VERSION "HIPBNYYYYYYYYYYYYYYYYYYYYYYYYYYYYYYYYYYYYY/4/%%%/4/'%**4YYY///"

NS_ :

BS_:

BU_: Aceinna

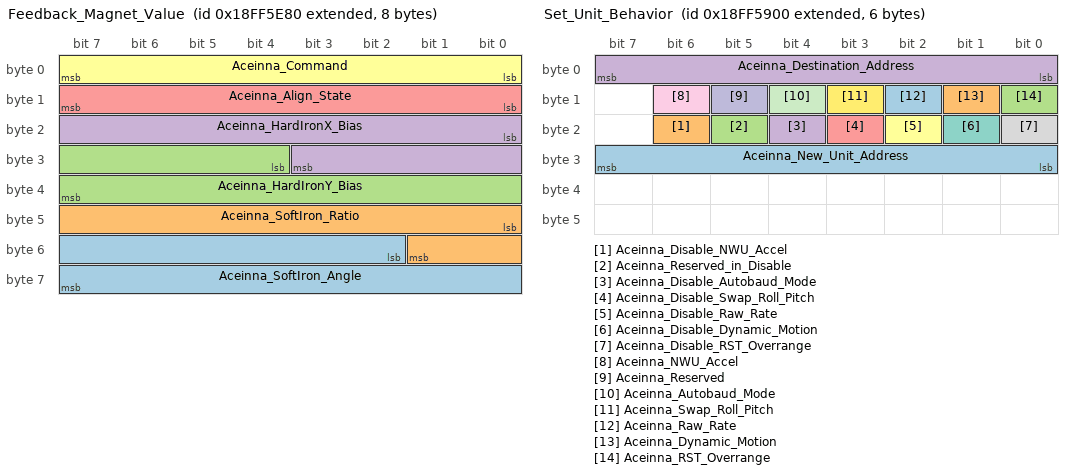
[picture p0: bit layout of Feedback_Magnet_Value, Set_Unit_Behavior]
BO_ 2566872704 Feedback_Magnet_Value: 8 Aceinna
 SG_ Aceinna_SoftIron_Angle : 50|14@1- (0.0015339,-3.14159) [-3.14|3.14] "rad" Vector__XXX
 SG_ Aceinna_SoftIron_Ratio : 40|10@1+ (0.0009765625,0) [0|0] "" Vector__XXX
 SG_ Aceinna_HardIronY_Bias : 28|12@1- (0.00390625,-8) [-8|8] "Gauss" Vector__XXX
 SG_ Aceinna_HardIronX_Bias : 16|12@1- (0.00390625,-8) [-8|8] "Gauss" Vector__XXX
 SG_ Aceinna_Align_State : 8|8@1+ (1,0) [0|0] "" Vector__XXX
 SG_ Aceinna_Command : 0|8@1+ (1,0) [0|0] "" Vector__XXX

BO_ 2566845313 Aceinna_GPS_lat_lon_: 8 Vector__XXX
 SG_ Aceinna_Lat : 0|32@1+ (0.0000001,-210) [-210|211] "deg" Vector__XXX
 SG_ Aceinna_Lon : 32|32@1+ (0.0000001,-210) [-210|211] "deg" Vector__XXX

BO_ 2566871296 Set_Unit_Behavior: 6 Vector__XXX
 SG_ Aceinna_New_Unit_Address : 24|8@1- (1,0) [0|0] "" Vector__XXX
 SG_ Aceinna_Disable_NWU_Accel : 22|1@1+ (1,0) [0|0] "" Vector__XXX
 SG_ Aceinna_Reserved_in_Disable : 21|1@1+ (1,0) [0|0] "" Vector__XXX
 SG_ Aceinna_Disable_Autobaud_Mode : 20|1@1+ (1,0) [0|0] "" Vector__XXX
 SG_ Aceinna_Disable_Swap_Roll_Pitch : 19|1@1+ (1,0) [0|0] "" Vector__XXX
 SG_ Aceinna_Disable_Raw_Rate : 18|1@1+ (1,0) [0|0] "" Vector__XXX
 SG_ Aceinna_Disable_Dynamic_Motion : 17|1@1+ (1,0) [0|0] "" Vector__XXX
 SG_ Aceinna_Disable_RST_Overrange : 16|1@1+ (1,0) [0|0] "" Vector__XXX
 SG_ Aceinna_NWU_Accel : 14|1@1+ (1,0) [0|0] "" Vector__XXX
 SG_ Aceinna_Reserved : 13|1@1+ (1,0) [0|0] "" Vector__XXX
 SG_ Aceinna_Autobaud_Mode : 12|1@1+ (1,0) [0|0] "" Vector__XXX
 SG_ Aceinna_Swap_Roll_Pitch : 11|1@1+ (1,0) [0|0] "" Vector__XXX
 SG_ Aceinna_Raw_Rate : 10|1@1+ (1,0) [0|0] "" Vector__XXX
 SG_ Aceinna_Dynamic_Motion : 9|1@1+ (1,0) [0|0] "" Vector__XXX
 SG_ Aceinna_RST_Overrange : 8|1@1+ (1,0) [0|0] "" Vector__XXX
 SG_ Aceinna_Destination_Address : 0|8@1- (1,0) [0|0] "" Vector__XXX

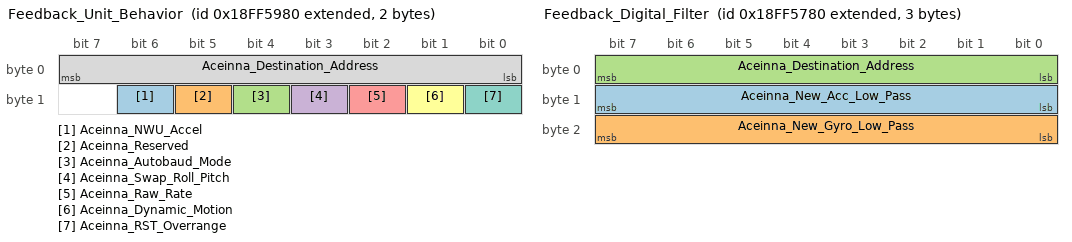
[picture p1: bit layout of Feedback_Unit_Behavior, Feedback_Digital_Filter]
BO_ 2566871424 Feedback_Unit_Behavior: 2 Vector__XXX
 SG_ Aceinna_NWU_Accel : 14|1@1+ (1,0) [0|0] "" Vector__XXX
 SG_ Aceinna_Reserved : 13|1@1+ (1,0) [0|0] "" Vector__XXX
 SG_ Aceinna_Autobaud_Mode : 12|1@1+ (1,0) [0|0] "" Vector__XXX
 SG_ Aceinna_Swap_Roll_Pitch : 11|1@1+ (1,0) [0|0] "" Vector__XXX
 SG_ Aceinna_Raw_Rate : 10|1@1+ (1,0) [0|0] "" Vector__XXX
 SG_ Aceinna_Dynamic_Motion : 9|1@1+ (1,0) [0|0] "" Vector__XXX
 SG_ Aceinna_RST_Overrange : 8|1@1+ (1,0) [0|0] "" Vector__XXX
 SG_ Aceinna_Destination_Address : 0|8@1- (1,0) [0|0] "" Vector__XXX

BO_ 2566870656 Feedback_Data_Pcket_Type: 2 Vector__XXX
 SG_ Aceinna_New_Packet_Type : 8|8@1- (1,0) [0|0] "" Vector__XXX
 SG_ Aceinna_Destination_Address : 0|8@1- (1,0) [0|0] "" Vector__XXX

BO_ 2566871168 Feedback_Orientation: 3 Vector__XXX
 SG_ Aceinna_New_Orientation_Type : 8|16@1- (1,0) [0|0] "" Vector__XXX
 SG_ Aceinna_Destination_Address : 0|8@1- (1,0) [0|0] "" Vector__XXX

BO_ 2566870912 Feedback_Digital_Filter: 3 Vector__XXX
 SG_ Aceinna_New_Acc_Low_Pass : 8|8@1- (1,0) [0|0] "" Vector__XXX
 SG_ Aceinna_New_Gyro_Low_Pass : 16|8@1- (1,0) [0|0] "" Vector__XXX
 SG_ Aceinna_Destination_Address : 0|8@1- (1,0) [0|0] "" Vector__XXX

BO_ 2566870400 Feedback_Packet_Rate_Divider: 2 Vector__XXX
 SG_ Aceinna_New_Pocket_Rate : 8|8@1- (1,0) [0|0] "" Vector__XXX
 SG_ Aceinna_Destination_Address : 0|8@1- (1,0) [0|0] "" Vector__XXX

BO_ 2565537536 Request_PGN: 3 Aceinna

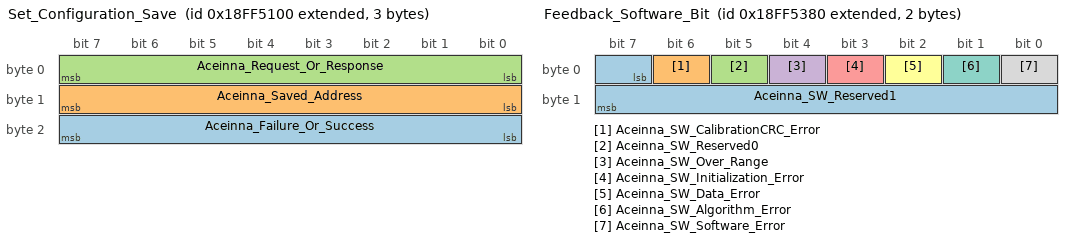
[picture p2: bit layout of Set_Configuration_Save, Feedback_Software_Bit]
BO_ 2566869248 Set_Configuration_Save: 3 Aceinna
 SG_ Aceinna_Failure_Or_Success : 16|8@1- (1,0) [0|0] "" Vector__XXX
 SG_ Aceinna_Saved_Address : 8|8@1- (1,0) [0|0] "" Vector__XXX
 SG_ Aceinna_Request_Or_Response : 0|8@1- (1,0) [0|0] "" Vector__XXX

BO_ 2566869888 Feedback_Software_Bit: 2 Aceinna
 SG_ Aceinna_SW_Reserved1 : 7|9@1+ (1,0) [0|0] "" Vector__XXX
 SG_ Aceinna_SW_CalibrationCRC_Error : 6|1@1+ (1,0) [0|0] "" Vector__XXX
 SG_ Aceinna_SW_Reserved0 : 5|1@1+ (1,0) [0|0] "" Vector__XXX
 SG_ Aceinna_SW_Over_Range : 4|1@1+ (1,0) [0|0] "" Vector__XXX
 SG_ Aceinna_SW_Initialization_Error : 3|1@1+ (1,0) [0|0] "" Vector__XXX
 SG_ Aceinna_SW_Data_Error : 2|1@1+ (1,0) [0|0] "" Vector__XXX
 SG_ Aceinna_SW_Algorithm_Error : 1|1@1+ (1,0) [0|0] "" Vector__XXX
 SG_ Aceinna_SW_Software_Error : 0|1@1+ (1,0) [0|0] "" Vector__XXX

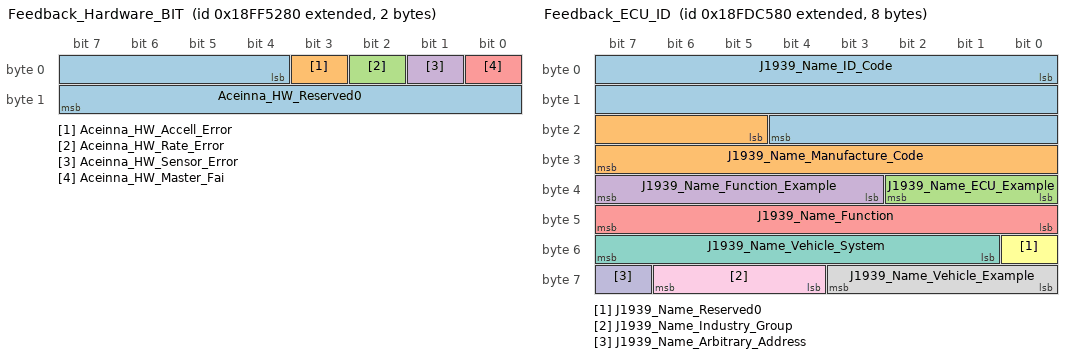
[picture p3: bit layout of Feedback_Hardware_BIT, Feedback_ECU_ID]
BO_ 2566869632 Feedback_Hardware_BIT: 2 Aceinna
 SG_ Aceinna_HW_Reserved0 : 4|12@1+ (1,0) [0|0] "" Vector__XXX
 SG_ Aceinna_HW_Accell_Error : 3|1@1+ (1,0) [0|0] "" Vector__XXX
 SG_ Aceinna_HW_Rate_Error : 2|1@1+ (1,0) [0|0] "" Vector__XXX
 SG_ Aceinna_HW_Sensor_Error : 1|1@1+ (1,0) [0|0] "" Vector__XXX
 SG_ Aceinna_HW_Master_Fai : 0|1@1+ (1,0) [0|0] "" Vector__XXX

BO_ 2566768000 Feedback_ECU_ID: 8 Aceinna
 SG_ J1939_Name_ID_Code : 0|21@1+ (1,0) [-16|15] "" Vector__XXX
 SG_ J1939_Name_Manufacture_Code : 21|11@1+ (1,0) [0|0] "" Vector__XXX
 SG_ J1939_Name_ECU_Example : 32|3@1+ (1,0) [-4|3] "" Vector__XXX
 SG_ J1939_Name_Function_Example : 35|5@1+ (1,0) [0|0] "" Vector__XXX
 SG_ J1939_Name_Function : 40|8@1+ (1,0) [0|0] "" Vector__XXX
 SG_ J1939_Name_Reserved0 : 48|1@1+ (1,0) [0|0] "" Vector__XXX
 SG_ J1939_Name_Vehicle_System : 49|7@1+ (1,0) [0|0] "" Vector__XXX
 SG_ J1939_Name_Vehicle_Example : 56|4@1+ (1,0) [0|0] "" Vector__XXX
 SG_ J1939_Name_Industry_Group : 60|3@1+ (1,0) [0|0] "" Vector__XXX
 SG_ J1939_Name_Arbitrary_Address : 63|1@1+ (1,0) [0|0] "" Vector__XXX

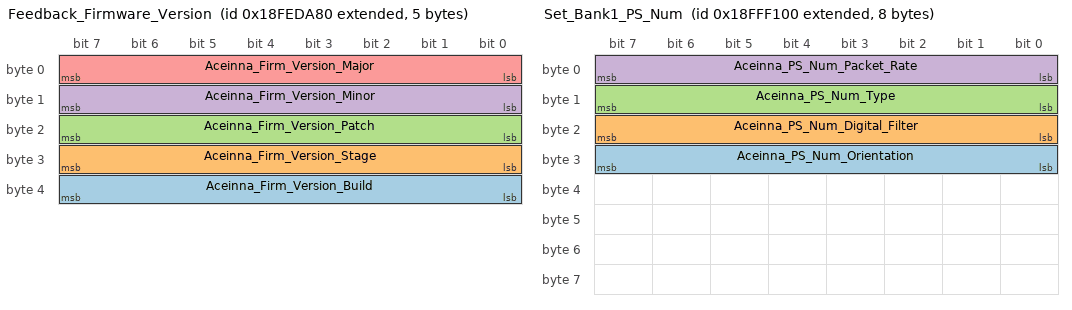
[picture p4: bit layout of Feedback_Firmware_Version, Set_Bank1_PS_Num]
BO_ 2566838912 Feedback_Firmware_Version: 5 Aceinna
 SG_ Aceinna_Firm_Version_Build : 32|8@1+ (1,0) [0|0] "" Vector__XXX
 SG_ Aceinna_Firm_Version_Stage : 24|8@1+ (1,0) [0|0] "" Vector__XXX
 SG_ Aceinna_Firm_Version_Patch : 16|8@1+ (1,0) [0|0] "" Vector__XXX
 SG_ Aceinna_Firm_Version_Minor : 8|8@1+ (1,0) [0|0] "" Vector__XXX
 SG_ Aceinna_Firm_Version_Major : 0|8@1+ (1,0) [0|0] "" Vector__XXX

BO_ 2566910208 Set_Bank1_PS_Num: 8 Aceinna
 SG_ Aceinna_PS_Num_Orientation : 24|8@1- (1,0) [0|0] "" Vector__XXX
 SG_ Aceinna_PS_Num_Digital_Filter : 16|8@1- (1,0) [0|0] "" Vector__XXX
 SG_ Aceinna_PS_Num_Type : 8|8@1- (1,0) [0|0] "" Vector__XXX
 SG_ Aceinna_PS_Num_Packet_Rate : 0|8@1- (1,0) [0|0] "" Vector__XXX

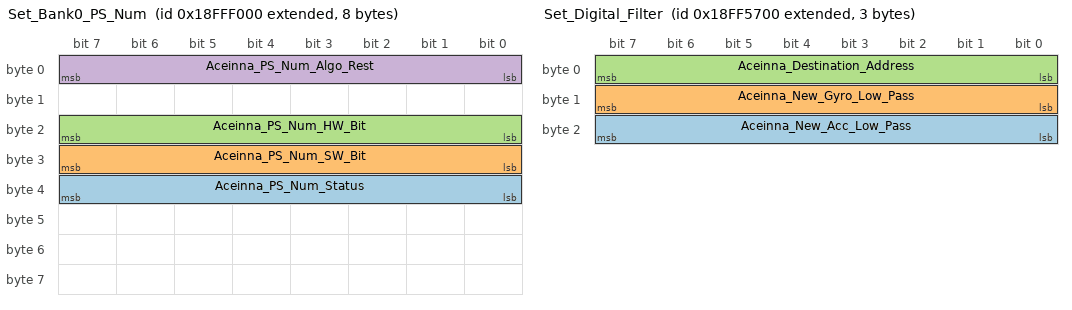
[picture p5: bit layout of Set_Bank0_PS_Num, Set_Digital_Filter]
BO_ 2566909952 Set_Bank0_PS_Num: 8 Aceinna
 SG_ Aceinna_PS_Num_Status : 32|8@1- (1,0) [0|0] "" Vector__XXX
 SG_ Aceinna_PS_Num_SW_Bit : 24|8@1- (1,0) [0|0] "" Vector__XXX
 SG_ Aceinna_PS_Num_HW_Bit : 16|8@1- (1,0) [0|0] "" Vector__XXX
 SG_ Aceinna_PS_Num_Algo_Rest : 0|8@1- (1,0) [0|0] "" Vector__XXX

BO_ 2566871040 Set_Orientation: 3 Aceinna
 SG_ Aceinna_New_Orientation_Type : 8|16@1- (1,0) [0|0] "" Vector__XXX
 SG_ Aceinna_Destination_Address : 0|8@1- (1,0) [0|0] "" Vector__XXX

BO_ 2566870784 Set_Digital_Filter: 3 Aceinna
 SG_ Aceinna_New_Acc_Low_Pass : 16|8@1- (1,0) [0|0] "" Vector__XXX
 SG_ Aceinna_New_Gyro_Low_Pass : 8|8@1- (1,0) [0|0] "" Vector__XXX
 SG_ Aceinna_Destination_Address : 0|8@1- (1,0) [0|0] "" Vector__XXX

BO_ 2566870528 Set_Data_Pcket_Type: 2 Aceinna
 SG_ Aceinna_New_Packet_Type : 8|8@1- (1,0) [0|0] "" Vector__XXX
 SG_ Aceinna_Destination_Address : 0|8@1- (1,0) [0|0] "" Vector__XXX

BO_ 2566870272 Set_Packet_Rate_Divider: 2 Aceinna
 SG_ Aceinna_New_Pocket_Rate : 8|8@1- (1,0) [0|0] "" Vector__XXX
 SG_ Aceinna_Destination_Address : 0|8@1- (1,0) [0|0] "" Vector__XXX

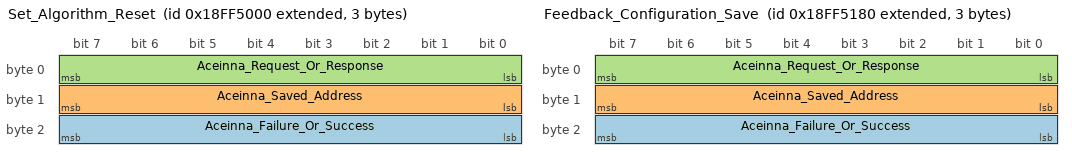
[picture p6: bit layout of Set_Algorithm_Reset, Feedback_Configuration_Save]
BO_ 2566868992 Set_Algorithm_Reset: 3 Aceinna
 SG_ Aceinna_Failure_Or_Success : 16|8@1- (1,0) [0|0] "" Vector__XXX
 SG_ Aceinna_Saved_Address : 8|8@1- (1,0) [0|0] "" Vector__XXX
 SG_ Aceinna_Request_Or_Response : 0|8@1- (1,0) [0|0] "" Vector__XXX

BO_ 2566869376 Feedback_Configuration_Save: 3 Aceinna
 SG_ Aceinna_Failure_Or_Success : 16|8@1+ (1,0) [0|0] "" Vector__XXX
 SG_ Aceinna_Saved_Address : 8|8@1+ (1,0) [0|0] "" Vector__XXX
 SG_ Aceinna_Request_Or_Response : 0|8@1+ (1,0) [0|0] "" Vector__XXX

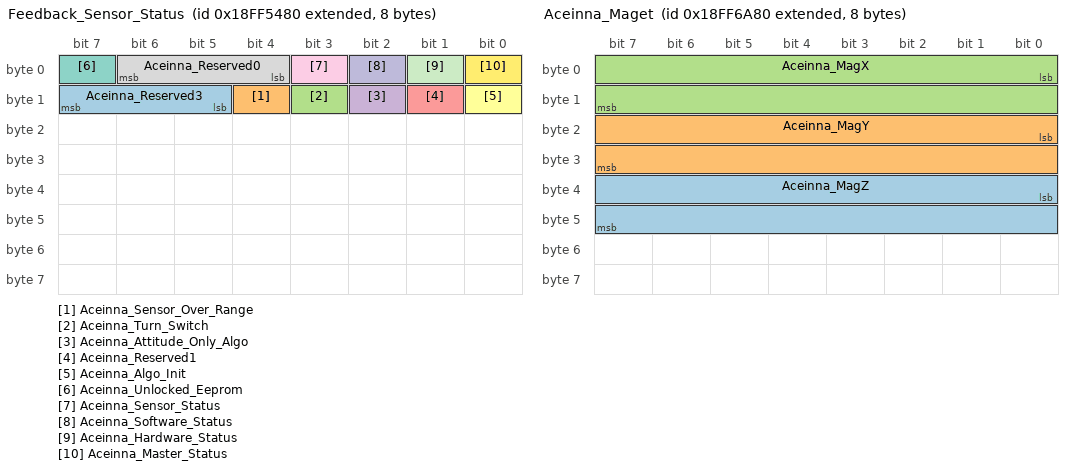
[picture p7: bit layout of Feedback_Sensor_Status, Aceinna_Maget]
BO_ 2566870144 Feedback_Sensor_Status: 8 Aceinna
 SG_ Aceinna_Reserved3 : 13|3@1+ (1,0) [0|7] "" Vector__XXX
 SG_ Aceinna_Sensor_Over_Range : 12|1@1+ (1,0) [0|1] "" Vector__XXX
 SG_ Aceinna_Turn_Switch : 11|1@1+ (1,0) [0|1] "" Vector__XXX
 SG_ Aceinna_Attitude_Only_Algo : 10|1@1+ (1,0) [0|1] "" Vector__XXX
 SG_ Aceinna_Reserved1 : 9|1@1+ (1,0) [0|7] "" Vector__XXX
 SG_ Aceinna_Algo_Init : 8|1@1+ (1,0) [0|1] "" Vector__XXX
 SG_ Aceinna_Unlocked_Eeprom : 7|1@1+ (1,0) [0|1] "" Vector__XXX
 SG_ Aceinna_Reserved0 : 4|3@1+ (1,0) [0|7] "" Vector__XXX
 SG_ Aceinna_Sensor_Status : 3|1@1+ (1,0) [0|1] "" Vector__XXX
 SG_ Aceinna_Software_Status : 2|1@1+ (1,0) [0|1] "" Vector__XXX
 SG_ Aceinna_Hardware_Status : 1|1@1+ (1,0) [0|1] "" Vector__XXX
 SG_ Aceinna_Master_Status : 0|1@1+ (1,0) [0|1] "N/A" Vector__XXX

BO_ 2566875776 Aceinna_Maget: 8 Vector__XXX
 SG_ Aceinna_MagZ : 32|16@1+ (0.00025,-8) [-8|8] "Gauss" Vector__XXX
 SG_ Aceinna_MagY : 16|16@1+ (0.00025,-8) [-8|8] "Gauss" Vector__XXX
 SG_ Aceinna_MagX : 0|16@1+ (0.00025,-8) [-8|8] "Gauss" Vector__XXX

BO_ 2566845312 Aceinna_GPS_lat_lon: 8 Aceinna
 SG_ Aceinna_Lat : 0|32@1+ (0.0000001,-210) [-210|211] "deg" Vector__XXX
 SG_ Aceinna_Lon : 32|32@1+ (0.0000001,-210) [-210|211] "deg" Vector__XXX

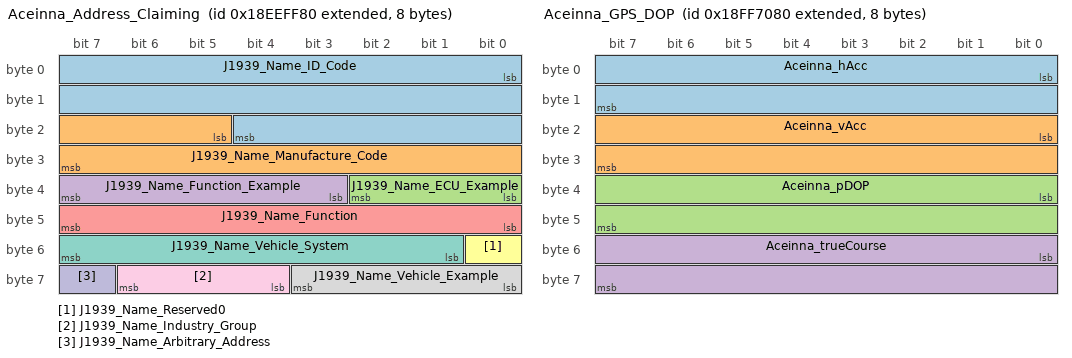
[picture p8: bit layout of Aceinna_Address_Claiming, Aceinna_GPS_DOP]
BO_ 2565799808 Aceinna_Address_Claiming: 8 Vector__XXX
 SG_ J1939_Name_ID_Code : 0|21@1+ (1,0) [-16|15] "" Vector__XXX
 SG_ J1939_Name_Manufacture_Code : 21|11@1+ (1,0) [0|0] "" Vector__XXX
 SG_ J1939_Name_ECU_Example : 32|3@1+ (1,0) [-4|3] "" Vector__XXX
 SG_ J1939_Name_Function_Example : 35|5@1+ (1,0) [0|0] "" Vector__XXX
 SG_ J1939_Name_Function : 40|8@1+ (1,0) [0|0] "" Vector__XXX
 SG_ J1939_Name_Reserved0 : 48|1@1+ (1,0) [0|0] "" Vector__XXX
 SG_ J1939_Name_Vehicle_System : 49|7@1+ (1,0) [0|0] "" Vector__XXX
 SG_ J1939_Name_Vehicle_Example : 56|4@1+ (1,0) [0|0] "" Vector__XXX
 SG_ J1939_Name_Industry_Group : 60|3@1+ (1,0) [0|0] "" Vector__XXX
 SG_ J1939_Name_Arbitrary_Address : 63|1@1+ (1,0) [0|0] "" Vector__XXX

BO_ 2566877312 Aceinna_GPS_DOP: 8 Aceinna
 SG_ Aceinna_hAcc : 0|16@1+ (1,0) [0|10000] "m" Vector__XXX
 SG_ Aceinna_vAcc : 16|16@1+ (1,0) [0|10000] "m" Vector__XXX
 SG_ Aceinna_pDOP : 32|16@1+ (0.01,0) [0|10000] "" Vector__XXX
 SG_ Aceinna_trueCourse : 48|16@1+ (0.01,0) [0|360] "deg" Vector__XXX

BO_ 2566876800 Aceinna_GPS_Speed: 8 Aceinna
 SG_ Aceinna_itow : 0|32@1+ (1,0) [0|604800000] "ms" Vector__XXX
 SG_ Aceinna_speed : 32|32@1+ (0.001,0) [-1000|1000] "m/s" Vector__XXX

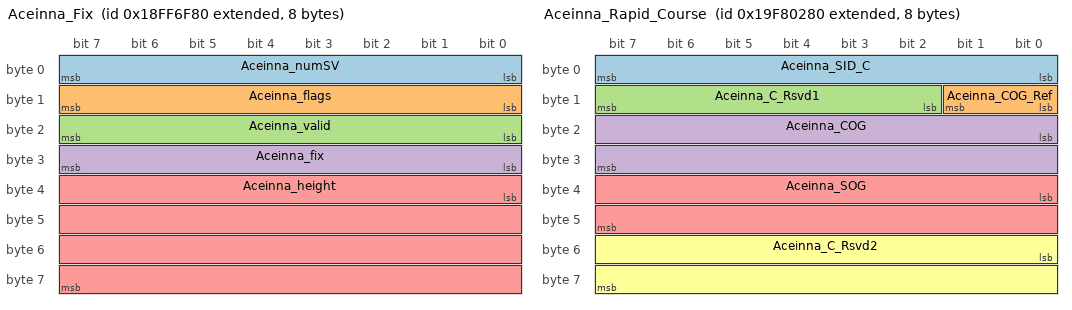
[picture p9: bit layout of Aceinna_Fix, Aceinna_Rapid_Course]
BO_ 2566877056 Aceinna_Fix: 8 Aceinna
 SG_ Aceinna_numSV : 0|8@1+ (1,0) [0|100] "" Vector__XXX
 SG_ Aceinna_flags : 8|8@1+ (0.000001,-210) [-210|211] "" Vector__XXX
 SG_ Aceinna_valid : 16|8@1+ (0.000001,-210) [-210|211] "" Vector__XXX
 SG_ Aceinna_fix : 24|8@1+ (1,0) [0|10] "" Vector__XXX
 SG_ Aceinna_height : 32|32@1+ (0.001,0) [-10000|10000] "m" Vector__XXX

BO_ 2583167360 Aceinna_Rapid_Position: 8 Aceinna
 SG_ Aceinna_RLat : 0|32@1+ (0.0000001,-210) [-210|211] "deg" Vector__XXX
 SG_ Aceinna_RLon : 32|32@1+ (0.0000001,-210) [-210|211] "deg" Vector__XXX

BO_ 2583167616 Aceinna_Rapid_Course: 8 Aceinna
 SG_ Aceinna_SID_C : 0|8@1+ (1,0) [0|0] "" Vector__XXX
 SG_ Aceinna_COG_Ref : 8|2@1+ (1,0) [0|0] "" Vector__XXX
 SG_ Aceinna_C_Rsvd1 : 10|6@1+ (1,0) [0|0] "" Vector__XXX
 SG_ Aceinna_COG : 16|16@1+ (0.0001,-3.141592653589) [-3.141592653589|3.141592653589] "rad" Vector__XXX
 SG_ Aceinna_SOG : 32|16@1+ (0.01,0) [0|0] "m/s" Vector__XXX
 SG_ Aceinna_C_Rsvd2 : 48|16@1+ (1,0) [0|0] "" Vector__XXX

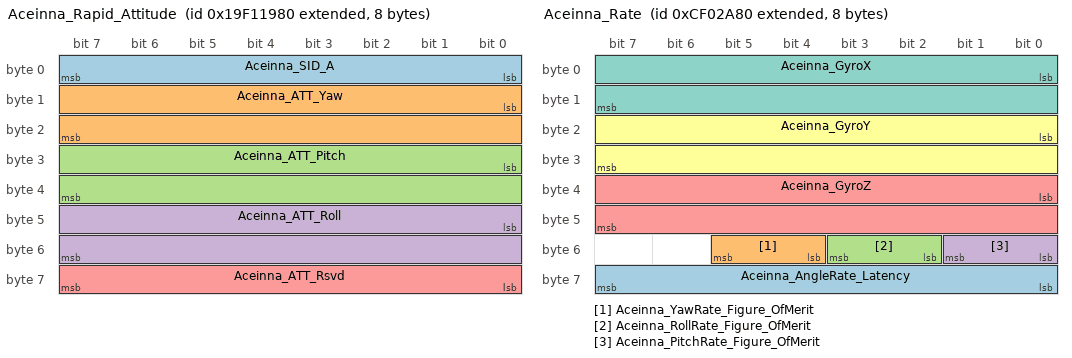
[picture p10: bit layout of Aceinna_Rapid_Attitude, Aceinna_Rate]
BO_ 2582714752 Aceinna_Rapid_Attitude: 8 Aceinna
 SG_ Aceinna_SID_A : 0|8@1+ (1,0) [0|0] "" Vector__XXX
 SG_ Aceinna_ATT_Yaw : 8|16@1+ (0.0001,-3.141592653589) [-3.141592653589|3.141592653589] "rad" Vector__XXX
 SG_ Aceinna_ATT_Pitch : 24|16@1+ (0.0001,-3.141592653589) [-3.141592653589|3.141592653589] "rad" Vector__XXX
 SG_ Aceinna_ATT_Roll : 40|16@1+ (0.0001,-3.141592653589) [-3.141592653589|3.141592653589] "rad" Vector__XXX
 SG_ Aceinna_ATT_Rsvd : 56|8@1+ (1,0) [0|0] "" Vector__XXX

BO_ 2364549760 Aceinna_Rate: 8 Aceinna
 SG_ Aceinna_AngleRate_Latency : 56|8@1+ (0.5,0) [0|0] "ms" Vector__XXX
 SG_ Aceinna_YawRate_Figure_OfMerit : 52|2@1+ (1,0) [0|0] "" Vector__XXX
 SG_ Aceinna_RollRate_Figure_OfMerit : 50|2@1+ (1,0) [0|0] "" Vector__XXX
 SG_ Aceinna_PitchRate_Figure_OfMerit : 48|2@1+ (1,0) [0|0] "" Vector__XXX
 SG_ Aceinna_GyroZ : 32|16@1+ (0.0078125,-250) [-250|261.9921875] "deg/s" Vector__XXX
 SG_ Aceinna_GyroY : 16|16@1+ (0.0078125,-250) [-250|261.9921875] "deg/s" Vector__XXX
 SG_ Aceinna_GyroX : 0|16@1+ (0.0078125,-250) [-250|261.9921875] "deg/s" Vector__XXX

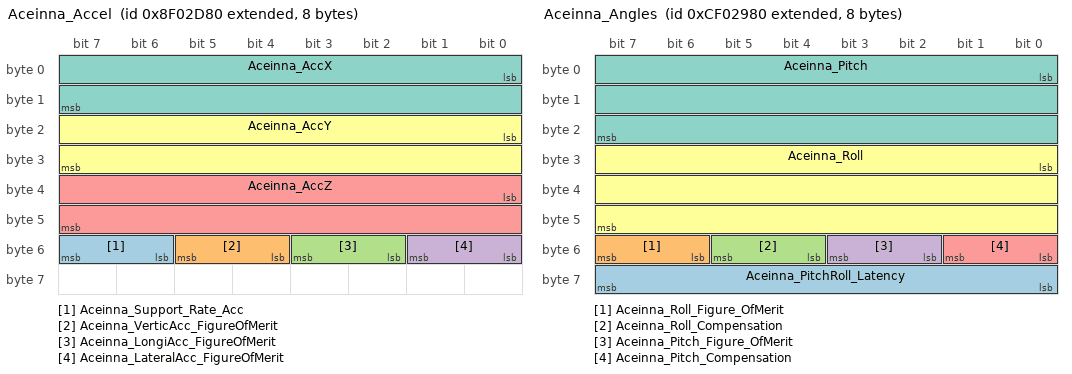
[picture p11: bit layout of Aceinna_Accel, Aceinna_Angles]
BO_ 2297441664 Aceinna_Accel: 8 Aceinna
 SG_ Aceinna_Support_Rate_Acc : 54|2@1+ (1,0) [0|0] "" Vector__XXX
 SG_ Aceinna_VerticAcc_FigureOfMerit : 52|2@1+ (1,0) [0|0] "" Vector__XXX
 SG_ Aceinna_LongiAcc_FigureOfMerit : 50|2@1+ (1,0) [0|0] "" Vector__XXX
 SG_ Aceinna_LateralAcc_FigureOfMerit : 48|2@1+ (1,0) [0|0] "" Vector__XXX
 SG_ Aceinna_AccZ : 32|16@1+ (0.01,-320) [-320|335.35] "m/s2" Vector__XXX
 SG_ Aceinna_AccY : 16|16@1+ (0.01,-320) [-320|335.35] "m/s2" Vector__XXX
 SG_ Aceinna_AccX : 0|16@1+ (0.01,-320) [-320|335.35] "m/s2" Vector__XXX

BO_ 2364549504 Aceinna_Angles: 8 Aceinna
 SG_ Aceinna_PitchRoll_Latency : 56|8@1+ (0.5,0) [0|0] "ms" Vector__XXX
 SG_ Aceinna_Roll_Figure_OfMerit : 54|2@1+ (1,0) [0|0] "" Vector__XXX
 SG_ Aceinna_Roll_Compensation : 52|2@1+ (1,0) [0|0] "" Vector__XXX
 SG_ Aceinna_Pitch_Figure_OfMerit : 50|2@1+ (1,0) [0|0] "" Vector__XXX
 SG_ Aceinna_Pitch_Compensation : 48|2@1+ (1,0) [0|0] "" Vector__XXX
 SG_ Aceinna_Roll : 24|24@1+ (0.000030517578125,-250) [-250|252] "deg" Vector__XXX
 SG_ Aceinna_Pitch : 0|24@1+ (0.000030517578125,-250) [-250|252] "deg" Vector__XXX

CM_ BU_ Aceinna "3 Dimension Gyro Module";
CM_ BO_ 2566872704 "feedback of Mag value";
CM_ BO_ 2566875776 "Magnetometer Data Packet";
CM_ SG_ 2566875776 Aceinna_MagZ "Magnetic Field Z";
CM_ SG_ 2566875776 Aceinna_MagY "Magnetic Field Y";
CM_ SG_ 2566875776 Aceinna_MagX "Magnetic Field X";
CM_ SG_ 2583167616 Aceinna_COG "heading";
CM_ SG_ 2583167616 Aceinna_SOG "V_ground";
BA_DEF_  "BusType" STRING ;
BA_DEF_ SG_  "IfcType" ENUM  "AlarmIfc","AliveIfc","Broadcast","CanReq","ConfigIfc","CounterIfc","CtrlIfc","ParamIfc","SignalIfc1","SignalIfc2","J1939","None","SafetyProtocol","CvuIfc","RioIfc","DevIfc","DiagIfc","J1939","ControlIfc","IndicatorIfc";
BA_DEF_ SG_  "SignalType" ENUM  "Data","ReqId","AliveCounter","ModuleStatus","AlarmId","AlarmStatus","Set","Type","FruidId","SetVal","ActVal","State","SetValNo","Sel","J1939Signal","CommandByte","DataByte","Crc","SequenceNumber","AliveMonitorStatus","AliveMonitorCounter","Startsign","Duration","OpCounter";
BA_DEF_ SG_  "GenSigSendType" ENUM  "Cyclic","OnWrite","OnWriteWithRepetition","OnChange","OnChangeWithRepetition","IfActive","IfActiveWithRepetition","NoSigSendType","vector_leerstring";
BA_DEF_ BO_  "VFrameFormat" ENUM  "StandardCAN","ExtendedCAN","reserved","J1939PG";
BA_DEF_ BO_  "J1939PGPrio" INT 0 7;
BA_DEF_ BO_  "GenMsgSendType " ENUM  "Cyclic","not_used","not_used","not_used","not_used","Cyclic","not_used","IfActive","NoMsgSendType";
BA_DEF_ BO_  "GenMsgSendType" ENUM  "Cyclic","NotUsed","NotUsed","NotUsed","NotUsed","Cyclic","NotUsed","IfActive","NoMsgSendType","NotUsed","vector_leerstring";
BA_DEF_ BU_  "TpOwnSystemEcuNumber" HEX 0 0;
BA_DEF_ BU_  "TpNodeBaseAddress" HEX 0 0;
BA_DEF_ BU_  "NmStationAddress" HEX 0 0;
BA_DEF_DEF_  "BusType" "";
BA_DEF_DEF_  "IfcType" "AlarmIfc";
BA_DEF_DEF_  "SignalType" "Data";
BA_DEF_DEF_  "GenSigSendType" "NoSigSendType";
BA_DEF_DEF_  "VFrameFormat" "J1939PG";
BA_DEF_DEF_  "J1939PGPrio" 6;
BA_DEF_DEF_  "GenMsgSendType " "NoMsgSendType";
BA_DEF_DEF_  "GenMsgSendType" "NoMsgSendType";
BA_DEF_DEF_  "TpOwnSystemEcuNumber" 0;
BA_DEF_DEF_  "TpNodeBaseAddress" 3290;
BA_DEF_DEF_  "NmStationAddress" 0;
BA_ "BusType" "CAN";
BA_ "TpOwnSystemEcuNumber" BU_ Aceinna 219;
BA_ "NmStationAddress" BU_ Aceinna 128;
BA_ "VFrameFormat" BO_ 2566872704 1;
BA_ "VFrameFormat" BO_ 2566875776 1;
BA_ "VFrameFormat" BO_ 2566845312 1;
BA_ "VFrameFormat" BO_ 2566877312 1;
BA_ "VFrameFormat" BO_ 2566876800 1;
BA_ "VFrameFormat" BO_ 2566877056 1;
BA_ "VFrameFormat" BO_ 2583167360 1;
BA_ "VFrameFormat" BO_ 2583167616 1;
BA_ "VFrameFormat" BO_ 2582714752 1;
BA_ "VFrameFormat" BO_ 2364549760 1;
BA_ "VFrameFormat" BO_ 2297441664 1;
BA_ "VFrameFormat" BO_ 2364549504 1;
